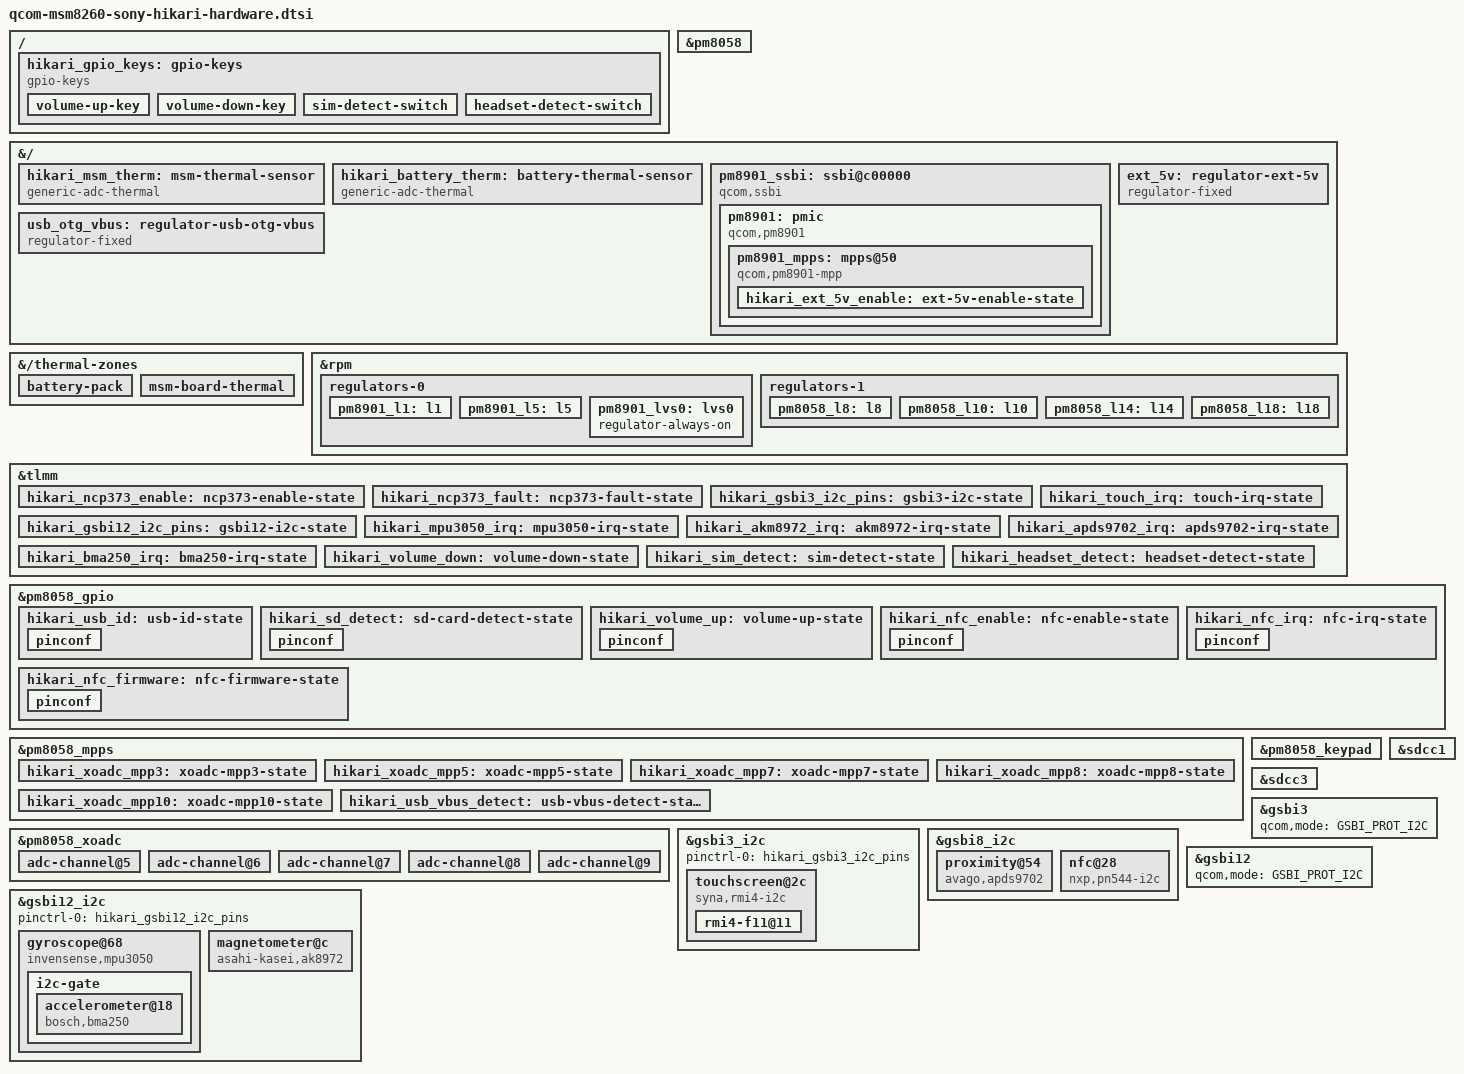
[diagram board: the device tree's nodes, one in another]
// SPDX-License-Identifier: GPL-2.0
/*
 * Sony Xperia acro S (Hikari) board hardware that is already backed by
 * physical inventory plus exact Fuji/Hikari downstream wiring and by an
 * existing mainline driver.  Keep speculative peripherals out of this file.
 */

#include <dt-bindings/input/input.h>
#include <dt-bindings/pinctrl/qcom,pmic-gpio.h>
#include <dt-bindings/pinctrl/qcom,pmic-mpp.h>
#include "pm8058.dtsi"

/* Fuji/Hikari routes the PM8058 interrupt to MSM TLMM GPIO88, active low. */
&pm8058 {
	interrupts-extended = <&tlmm 88 IRQ_TYPE_LEVEL_LOW>;
};

/* MSM8x60's second SSBI arbiter connects the four-MPP PM8901. */
&{/} {
	/*
	 * Fuji's board thermistor is routed through PM8058 MPP10 to XOADC
	 * AMUX7.  The voltage/temperature curve is the exact scale_msm_therm
	 * table from Sony's board kernel, expressed in the units returned by
	 * the mainline XOADC consumer API (microvolts and millicelsius).
	 */
	hikari_msm_therm: msm-thermal-sensor {
		compatible = "generic-adc-thermal";
		#thermal-sensor-cells = <0>;
		io-channels = <&pm8058_xoadc 0x00 0x07>;
		io-channel-names = "sensor-channel";
		temperature-lookup-table = <
			(-30000) 2150000
			(-20000) 2107000
			(-10000) 2037000
			(0)      1929000
			(10000)  1776000
			(20000)  1579000
			(25000)  1467000
			(30000)  1349000
			(40000)  1108000
			(50000)   878000
			(60000)   677000
			(70000)   513000
			(80000)   385000
			(90000)   287000
			(100000)  215000
			(110000)  186000
			(120000)  107000
		>;
	};

	/*
	 * The removable pack NTC is fed from L18 (2.2 V) through 100 kOhm.
	 * Hikari accepts two Sony battery families whose non-overlapping
	 * resistance ranges allow one voltage-ordered table to describe both.
	 */
	hikari_battery_therm: battery-thermal-sensor {
		compatible = "generic-adc-thermal";
		#thermal-sensor-cells = <0>;
		io-channels = <&pm8058_xoadc 0x00 0x06>;
		io-channel-names = "sensor-channel";
		temperature-lookup-table = <
			(-20000) 1416245
			(0)      1353846
			(5000)   1329402
			(10000)  1301674
			(15000)  1270946
			(20000)  1238041
			(25000)  1204525
			(30000)  1171001
			(35000)  1138736
			(40000)  1108189
			(45000)  1080407
			(50000)  1055359
			(55000)  1033510
			(60000)  1014655
			(65000)   997814
			(70000)   983858
			(100000)  934905
			(-20000)  885783
			(0)       725469
			(5000)    674341
			(10000)   621808
			(15000)   570370
			(20000)   520611
			(25000)   473155
			(30000)   430088
			(35000)   392276
			(40000)   357454
			(45000)   327660
			(50000)   301812
			(55000)   280279
			(60000)   261674
			(65000)   244444
			(70000)   232200
			(100000)  185348
		>;
	};

	pm8901_ssbi: ssbi@c00000 {
		compatible = "qcom,ssbi";
		reg = <0x00c00000 0x1000>;
		qcom,controller-type = "pmic-arbiter";

		pm8901: pmic {
			compatible = "qcom,pm8901";
			interrupt-parent = <&tlmm>;
			interrupts = <91 IRQ_TYPE_LEVEL_LOW>;
			#interrupt-cells = <2>;
			interrupt-controller;
			#address-cells = <1>;
			#size-cells = <0>;

			pm8901_mpps: mpps@50 {
				compatible = "qcom,pm8901-mpp", "qcom,ssbi-mpp";
				reg = <0x50>;
				gpio-controller;
				#gpio-cells = <2>;
				gpio-ranges = <&pm8901_mpps 0 0 4>;
				interrupt-controller;
				#interrupt-cells = <2>;

				hikari_ext_5v_enable: ext-5v-enable-state {
					pins = "mpp1";
					function = "digital";
					output-low;
					power-source = <PM8901_MPP_MSMIO>;
				};
			};
		};
	};

	ext_5v: regulator-ext-5v {
		compatible = "regulator-fixed";
		regulator-name = "ext-5v";
		regulator-min-microvolt = <5000000>;
		regulator-max-microvolt = <5000000>;
		vin-supply = <&usb_otg_guard>;
		/* The BQ24160 parent driver registers this child regulator. */
		post-init-providers = <&usb_otg_guard>;
		gpio = <&pm8901_mpps 1 GPIO_ACTIVE_HIGH>;
		enable-active-high;
		pinctrl-names = "default";
		pinctrl-0 = <&hikari_ext_5v_enable>;
	};

	usb_otg_vbus: regulator-usb-otg-vbus {
		compatible = "regulator-fixed";
		regulator-name = "usb-otg-vbus";
		regulator-min-microvolt = <5000000>;
		regulator-max-microvolt = <5000000>;
		vin-supply = <&ext_5v>;
		gpio = <&tlmm 28 GPIO_ACTIVE_HIGH>;
		enable-active-high;
		startup-delay-us = <1000>;
		interrupt-parent = <&tlmm>;
		interrupts = <104 IRQ_TYPE_EDGE_FALLING>;
		pinctrl-names = "default";
		pinctrl-0 = <&hikari_ncp373_enable &hikari_ncp373_fault>;
	};
};

&{/thermal-zones} {
	battery-pack {
		polling-delay-passive = <2000>;
		polling-delay = <10000>;
		thermal-sensors = <&hikari_battery_therm>;
	};

	msm-board-thermal {
		polling-delay-passive = <1000>;
		polling-delay = <5000>;
		thermal-sensors = <&hikari_msm_therm>;
	};
};

/*
 * Exact downstream rails:
 *   ClearPad VDD        = PM8901 L1, 3.05 V
 *   SDCC1/eMMC VDD     = PM8901 L5, 2.85 V, always on
 *   SDCC1/eMMC VCCQ    = PM8901 LVS0, always on
 *   shared sensor VIO  = PM8058 L8, 1.80 V, enabled at board init
 *   shared sensor VDD  = PM8058 L10, 2.85 V, enabled at board init
 *   SDCC3/microSD VDD  = PM8058 L14, 2.85 V
 */
&rpm {
	regulators-0 {
		pm8901_l1: l1 {
			regulator-min-microvolt = <3050000>;
			regulator-max-microvolt = <3050000>;
		};

		pm8901_l5: l5 {
			regulator-min-microvolt = <2850000>;
			regulator-max-microvolt = <2850000>;
			regulator-always-on;
		};

		pm8901_lvs0: lvs0 {
			regulator-always-on;
		};
	};

	regulators-1 {
		pm8058_l8: l8 {
			regulator-min-microvolt = <1800000>;
			regulator-max-microvolt = <1800000>;
			regulator-always-on;
		};

		pm8058_l10: l10 {
			regulator-min-microvolt = <2850000>;
			regulator-max-microvolt = <2850000>;
			regulator-always-on;
		};

		pm8058_l14: l14 {
			regulator-min-microvolt = <2850000>;
			regulator-max-microvolt = <2850000>;
		};

		/* Fuji/Hikari uses L18 as the 2.2 V XOADC reference supply. */
		pm8058_l18: l18 {
			regulator-min-microvolt = <2200000>;
			regulator-max-microvolt = <2200000>;
		};
	};
};

&tlmm {
	hikari_ncp373_enable: ncp373-enable-state {
		pins = "gpio28";
		function = "gpio";
		drive-strength = <2>;
		bias-disable;
		output-low;
	};

	hikari_ncp373_fault: ncp373-fault-state {
		pins = "gpio104";
		function = "gpio";
		drive-strength = <2>;
		bias-disable;
	};
	hikari_gsbi3_i2c_pins: gsbi3-i2c-state {
		pins = "gpio43", "gpio44";
		function = "gsbi3";
		drive-strength = <8>;
		bias-disable;
	};

	hikari_touch_irq: touch-irq-state {
		pins = "gpio127";
		function = "gpio";
		input-enable;
		bias-disable;
	};

	hikari_gsbi12_i2c_pins: gsbi12-i2c-state {
		pins = "gpio115", "gpio116";
		function = "gsbi12";
		drive-strength = <16>;
		bias-disable;
	};

	hikari_mpu3050_irq: mpu3050-irq-state {
		pins = "gpio30";
		function = "gpio";
		input-enable;
		bias-disable;
	};

	hikari_akm8972_irq: akm8972-irq-state {
		pins = "gpio31";
		function = "gpio";
		input-enable;
		bias-disable;
	};

	hikari_apds9702_irq: apds9702-irq-state {
		pins = "gpio34";
		function = "gpio";
		input-enable;
		bias-disable;
	};

	hikari_bma250_irq: bma250-irq-state {
		pins = "gpio41";
		function = "gpio";
		input-enable;
		bias-disable;
	};

	hikari_volume_down: volume-down-state {
		pins = "gpio73";
		function = "gpio";
		input-enable;
		bias-disable;
	};

	hikari_sim_detect: sim-detect-state {
		pins = "gpio94";
		function = "gpio";
		input-enable;
		bias-disable;
	};

	/* Sony's simple-remote driver uses TLMM61 as the plug-presence IRQ. */
	hikari_headset_detect: headset-detect-state {
		pins = "gpio61";
		function = "gpio";
		input-enable;
		bias-disable;
	};
};

/* PM8058 GPIO22 is the Hikari microSD card-detect input, active low. */
&pm8058_gpio {
	/* PM8058 GPIO31: USB ID, legacy zero-based index 30. */
	hikari_usb_id: usb-id-state {
		pinconf {
			pins = "gpio31";
			function = "normal";
			input-enable;
			bias-pull-up;
			qcom,pull-up-strength = <PMIC_GPIO_PULL_UP_1P5>;
			power-source = <PM8058_GPIO_S3>;
		};
	};
	hikari_sd_detect: sd-card-detect-state {
		pinconf {
			pins = "gpio22";
			function = "normal";
			input-enable;
			bias-pull-up;
			qcom,pull-up-strength = <PMIC_GPIO_PULL_UP_30>;
		};
	};

	/* Sony configures PM8058 GPIO26 as the wake-capable volume-up input. */
	hikari_volume_up: volume-up-state {
		pinconf {
			pins = "gpio26";
			function = "normal";
			input-enable;
			bias-disable;
			power-source = <PM8058_GPIO_S3>;
		};
	};

	/* PN544 VEN is PM8058 GPIO17, open drain from VPH on Hikari ROW. */
	hikari_nfc_enable: nfc-enable-state {
		pinconf {
			pins = "gpio17";
			function = "normal";
			output-low;
			bias-disable;
			drive-open-drain;
			power-source = <PM8058_GPIO_VPH>;
			qcom,drive-strength = <PMIC_GPIO_STRENGTH_MED>;
		};
	};

	/* PN544 firmware-download select is PM8058 GPIO27 from S3. */
	hikari_nfc_firmware: nfc-firmware-state {
		pinconf {
			pins = "gpio27";
			function = "normal";
			output-low;
			bias-disable;
			power-source = <PM8058_GPIO_S3>;
			qcom,drive-strength = <PMIC_GPIO_STRENGTH_LOW>;
		};
	};

	/* PN544 IRQ is PM8058 GPIO28, pulled down and sampled on a rising edge. */
	hikari_nfc_irq: nfc-irq-state {
		pinconf {
			pins = "gpio28";
			function = "normal";
			input-enable;
			bias-pull-down;
			power-source = <PM8058_GPIO_S3>;
		};
	};
};

&pm8058_mpps {
	/*
	 * Exact Fuji/Hikari XOADC routing from board-semc_fuji.c:
	 * MPP3 -> AMUX5 (headset), MPP7 -> AMUX6 (battery thermistor),
	 * MPP10 -> AMUX7 (MSM thermistor), MPP8 -> AMUX8 (battery ID),
	 * and MPP5 -> AMUX9 (charger current monitor).
	 */
	hikari_xoadc_mpp3: xoadc-mpp3-state {
		pins = "mpp3";
		function = "analog";
		input-enable;
		bias-high-impedance;
		qcom,amux-route = <PMIC_MPP_AMUX_ROUTE_CH5>;
	};

	hikari_xoadc_mpp5: xoadc-mpp5-state {
		pins = "mpp5";
		function = "analog";
		input-enable;
		bias-high-impedance;
		/* Value 4 is AMUX9 on the SSBI PM8058 MPP controller. */
		qcom,amux-route = <4>;
	};

	hikari_xoadc_mpp7: xoadc-mpp7-state {
		pins = "mpp7";
		function = "analog";
		input-enable;
		bias-high-impedance;
		qcom,amux-route = <PMIC_MPP_AMUX_ROUTE_CH6>;
	};

	hikari_xoadc_mpp8: xoadc-mpp8-state {
		pins = "mpp8";
		function = "analog";
		input-enable;
		bias-high-impedance;
		qcom,amux-route = <PMIC_MPP_AMUX_ROUTE_CH8>;
	};

	hikari_xoadc_mpp10: xoadc-mpp10-state {
		pins = "mpp10";
		function = "analog";
		input-enable;
		bias-high-impedance;
		qcom,amux-route = <PMIC_MPP_AMUX_ROUTE_CH7>;
	};

	/* PM8058 MPP11: VBUS detect, legacy zero-based index 10. */
	hikari_usb_vbus_detect: usb-vbus-detect-state {
		pins = "mpp11";
		function = "digital";
		input-enable;
		power-source = <PM8058_MPP_S3>;
	};
};

&pm8058_xoadc {
	xoadc-ref-supply = <&pm8058_l18>;
	pinctrl-names = "default";
	pinctrl-0 = <&hikari_xoadc_mpp3 &hikari_xoadc_mpp5
		     &hikari_xoadc_mpp7 &hikari_xoadc_mpp8
		     &hikari_xoadc_mpp10>;

	adc-channel@5 {
		reg = <0x00 0x05>;
		label = "headset-accessory";
	};

	adc-channel@6 {
		reg = <0x00 0x06>;
		label = "battery-thermistor";
	};

	adc-channel@7 {
		reg = <0x00 0x07>;
		label = "msm-thermistor";
	};

	adc-channel@8 {
		reg = <0x00 0x08>;
		label = "battery-id";
	};

	adc-channel@9 {
		reg = <0x00 0x09>;
		label = "charger-current-monitor";
	};
};

/*
 * Exact Hikari physical keys from keypad-fuji_hikari.c.  Camera focus and
 * shutter use the PM8058 5x5 matrix at row 1, columns 0/1.  The old board
 * data used 15 ms debounce, 2 ms scan delay and 122 us row hold and allowed
 * the matrix to wake the phone.
 */
&pm8058_keypad {
	linux,keymap = <
		MATRIX_KEY(1, 0, KEY_CAMERA_FOCUS)
		MATRIX_KEY(1, 1, KEY_CAMERA)
	>;
	keypad,num-rows = <5>;
	keypad,num-columns = <5>;
	debounce = <15>;
	scan-delay = <2>;
	row-hold = <122000>;
	wakeup-source;
};

/ {
	hikari_gpio_keys: gpio-keys {
		compatible = "gpio-keys";
		pinctrl-names = "default";
		pinctrl-0 = <&hikari_volume_up &hikari_volume_down
			     &hikari_sim_detect &hikari_headset_detect>;

		volume-up-key {
			label = "Volume Up";
			linux,code = <KEY_VOLUMEUP>;
			/* Sony reads the PMIC real-time bit inverted: asserted is low. */
			gpios = <&pm8058_gpio 25 GPIO_ACTIVE_LOW>;
			debounce-interval = <10>;
			wakeup-source;
		};

		volume-down-key {
			label = "Volume Down";
			linux,code = <KEY_VOLUMEDOWN>;
			gpios = <&tlmm 73 GPIO_ACTIVE_HIGH>;
			debounce-interval = <10>;
			wakeup-source;
		};

		sim-detect-switch {
			label = "SIM detection";
			linux,input-type = <EV_SW>;
			linux,code = <SW_JACK_PHYSICAL_INSERT>;
			gpios = <&tlmm 94 GPIO_ACTIVE_HIGH>;
			debounce-interval = <100>;
			wakeup-source;
		};

		headset-detect-switch {
			label = "Headset detection";
			linux,input-type = <EV_SW>;
			linux,code = <SW_HEADPHONE_INSERT>;
			/* Physical testing and Sony's inverted status path: high = inserted. */
			gpios = <&tlmm 61 GPIO_ACTIVE_HIGH>;
			debounce-interval = <1500>;
			wakeup-source;
		};
	};
};

/* Physical inventory: MAG2GA eMMC on MSM SDCC1, 8-bit. */
&sdcc1 {
	vmmc-supply = <&pm8901_l5>;
	vqmmc-supply = <&pm8901_lvs0>;
	status = "okay";
};

/* Physical inventory: removable microSD slot on MSM SDCC3. */
&sdcc3 {
	vmmc-supply = <&pm8058_l14>;
	cd-gpios = <&pm8058_gpio 21 GPIO_ACTIVE_LOW>;
	pinctrl-names = "default";
	pinctrl-0 = <&hikari_sd_detect>;
	status = "okay";
};

/*
 * Hikari ClearPad is a Synaptics RMI4 device on GSBI3 I2C address 0x2c.
 * Sony's legacy driver used F11 and a falling-edge IRQ on TLMM GPIO127.
 * Its pointer area is 720x1280; the extra strip below Y=1279 was translated
 * by Sony-specific software into BACK/HOME/MENU virtual keys, so do not
 * invent an F1A hardware function here.
 */
&gsbi3 {
	qcom,mode = <GSBI_PROT_I2C>;
	status = "okay";
};

&gsbi3_i2c {
	pinctrl-names = "default";
	pinctrl-0 = <&hikari_gsbi3_i2c_pins>;
	status = "okay";

	touchscreen@2c {
		compatible = "syna,rmi4-i2c";
		reg = <0x2c>;
		interrupts-extended = <&tlmm 127 IRQ_TYPE_EDGE_FALLING>;
		pinctrl-names = "default";
		pinctrl-0 = <&hikari_touch_irq>;
		vdd-supply = <&pm8901_l1>;
		/* Hikari has one 3.05 V ClearPad rail.  RMI4 names both
		 * logical consumers, so both map to the same physical supply. */
		vio-supply = <&pm8901_l1>;
		/* Sony's ClearPad driver waits 400 ms after enabling this rail. */
		syna,startup-delay-ms = <400>;
		#address-cells = <1>;
		#size-cells = <0>;

		rmi4-f11@11 {
			reg = <0x11>;
			syna,sensor-type = <1>;
			syna,clip-x-high = <719>;
			syna,clip-y-high = <1279>;
		};
	};
};

/*
 * GSBI8 also carries the PN544 NFC controller.  Sony registers it at 0x28,
 * with rising-edge IRQ on PM8058 GPIO28, VEN on GPIO17 and FWDL on GPIO27.
 * The mainline PN544 HCI driver owns the exact OFF/ON/FWDL toggle sequence.
 */
&gsbi8_i2c {
	proximity@54 {
		compatible = "avago,apds9702";
		reg = <0x54>;
		interrupts-extended = <&tlmm 34 IRQ_TYPE_EDGE_BOTH>;
		dout-gpios = <&tlmm 34 GPIO_ACTIVE_LOW>;
		pinctrl-names = "default";
		pinctrl-0 = <&hikari_apds9702_irq>;
		/* Exact Hikari trg/pwr/burst/freq/duration/threshold/filter. */
		avago,control-word = <0xdfbc>;
		wakeup-source;
	};

	nfc@28 {
		compatible = "nxp,pn544-i2c";
		reg = <0x28>;
		interrupts-extended = <&pm8058_gpio 27 IRQ_TYPE_EDGE_RISING>;
		enable-gpios = <&pm8058_gpio 16 GPIO_ACTIVE_HIGH>;
		firmware-gpios = <&pm8058_gpio 26 GPIO_ACTIVE_HIGH>;
		pinctrl-names = "default";
		pinctrl-0 = <&hikari_nfc_enable &hikari_nfc_firmware &hikari_nfc_irq>;
	};
};

/*
 * Motion stack.  Hikari's exact downstream data places MPU3050 on GSBI12
 * primary I2C and BMA250 on the MPU3050 secondary bus.  Use the mainline
 * MPU3050 i2c-gate instead of carrying the old InvenSense MPL glue.
 */
&gsbi12 {
	qcom,mode = <GSBI_PROT_I2C>;
	status = "okay";
};

&gsbi12_i2c {
	pinctrl-names = "default";
	pinctrl-0 = <&hikari_gsbi12_i2c_pins>;
	status = "okay";

	gyroscope@68 {
		compatible = "invensense,mpu3050";
		reg = <0x68>;
		vlogic-supply = <&pm8058_l8>;
		vdd-supply = <&pm8058_l10>;
		interrupts-extended = <&tlmm 30 IRQ_TYPE_EDGE_RISING>;
		pinctrl-names = "default";
		pinctrl-0 = <&hikari_mpu3050_irq>;
		mount-matrix = "0", "1", "0",
			       "1", "0", "0",
			       "0", "0", "-1";

		i2c-gate {
			#address-cells = <1>;
			#size-cells = <0>;

			accelerometer@18 {
				compatible = "bosch,bma250";
				reg = <0x18>;
				vddio-supply = <&pm8058_l8>;
				vdd-supply = <&pm8058_l10>;
				interrupts-extended = <&tlmm 41 IRQ_TYPE_EDGE_RISING>;
				pinctrl-names = "default";
				pinctrl-0 = <&hikari_bma250_irq>;
				mount-matrix = "1", "0", "0",
					       "0", "-1", "0",
					       "0", "0", "-1";
			};
		};
	};

	magnetometer@c {
		compatible = "asahi-kasei,ak8972";
		reg = <0x0c>;
		vdd-supply = <&pm8058_l10>;
		vid-supply = <&pm8058_l8>;
		interrupts-extended = <&tlmm 31 IRQ_TYPE_LEVEL_HIGH>;
		pinctrl-names = "default";
		pinctrl-0 = <&hikari_akm8972_irq>;
		mount-matrix = "-1", "0", "0",
			       "0", "1", "0",
			       "0", "0", "-1";
	};
};
